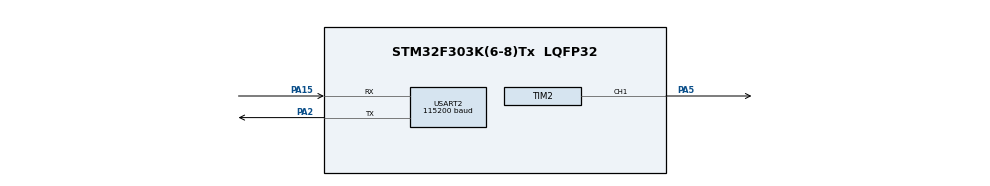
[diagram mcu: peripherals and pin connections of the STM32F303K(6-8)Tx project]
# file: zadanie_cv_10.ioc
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Dma.Request0=USART2_RX
Dma.Request1=USART2_TX
Dma.USART2_RX.0.Direction=DMA_PERIPH_TO_MEMORY
Dma.USART2_RX.0.Instance=DMA1_Channel6
Dma.USART2_RX.0.MemDataAlignment=DMA_MDATAALIGN_BYTE
Dma.USART2_RX.0.MemInc=DMA_MINC_ENABLE
Dma.USART2_RX.0.Mode=DMA_CIRCULAR
Dma.USART2_RX.0.PeriphDataAlignment=DMA_PDATAALIGN_BYTE
Dma.USART2_RX.0.PeriphInc=DMA_PINC_DISABLE
Dma.USART2_RX.0.Priority=DMA_PRIORITY_MEDIUM
Dma.USART2_TX.1.Direction=DMA_MEMORY_TO_PERIPH
Dma.USART2_TX.1.Instance=DMA1_Channel7
Dma.USART2_TX.1.MemDataAlignment=DMA_MDATAALIGN_BYTE
Dma.USART2_TX.1.MemInc=DMA_MINC_ENABLE
Dma.USART2_TX.1.Mode=DMA_NORMAL
Dma.USART2_TX.1.PeriphDataAlignment=DMA_PDATAALIGN_BYTE
Dma.USART2_TX.1.PeriphInc=DMA_PINC_DISABLE
Dma.USART2_TX.1.Priority=DMA_PRIORITY_MEDIUM
Mcu.Family=STM32F3
Mcu.Name=STM32F303K(6-8)Tx
Mcu.Package=LQFP32
NVIC.DMA1_Channel6_IRQn=true\:0\:0\:false\:false\:true\:false\:true
NVIC.DMA1_Channel7_IRQn=true\:0\:0\:false\:false\:true\:false\:true
NVIC.PriorityGroup=NVIC_PRIORITYGROUP_4
NVIC.TIM2_IRQn=true\:0\:0\:false\:false\:true\:true\:true
NVIC.USART2_IRQn=true\:0\:0\:false\:false\:true\:true\:true
PA15.Mode=Asynchronous
PA15.Signal=USART2_RX
PA2.Mode=Asynchronous
PA2.Signal=USART2_TX
PA5.Signal=S_TIM2_CH1_ETR
ProjectManager.HeapSize=0x200
ProjectManager.StackSize=0x400
ProjectManager.TargetToolchain=STM32CubeIDE
RCC.AHBFreq_Value=8000000
RCC.APB1Freq_Value=8000000
RCC.APB2Freq_Value=8000000
RCC.CortexFreq_Value=8000000
RCC.HSE_VALUE=8000000
RCC.HSI_VALUE=8000000
RCC.SYSCLKFreq_VALUE=8000000
SH.S_TIM2_CH1_ETR.0=TIM2_CH1,PWM Generation1 CH1
TIM2.Channel-PWM\ Generation1\ CH1=TIM_CHANNEL_1
TIM2.Period=9
TIM2.Prescaler=7999
USART2.BaudRate=115200
USART2.VirtualMode-Asynchronous=VM_ASYNC
VP_TIM2_VS_ClockSourceINT.Mode=Internal
board=NUCLEO-F303K8

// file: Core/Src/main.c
 /* USER CODE BEGIN Header */
/**
  ******************************************************************************
  * @file           : main.c
  * @brief          : Main program body
  ******************************************************************************
  * @attention
  *
  * <h2><center>&copy; Copyright (c) 2021 STMicroelectronics.
  * All rights reserved.</center></h2>
  *
  * This software component is licensed by ST under BSD 3-Clause license,
  * the "License"; You may not use this file except in compliance with the
  * License. You may obtain a copy of the License at:
  *                        opensource.org/licenses/BSD-3-Clause
  *
  ******************************************************************************
  */
/* USER CODE END Header */
#include "main.h"
#include "dma.h"
#include "tim.h"
#include "usart.h"
#include "gpio.h"
#include "stm32f3xx_it.h"
#include <string.h>

void SystemClock_Config(void);

/* USER CODE BEGIN 0 */
void proccesDmaData(const uint8_t* sign, uint8_t length);
/* USER CODE END 0 */
uint8_t is_dollar = 0;
uint8_t is_manual = 0;
int main(void)
{

  /* MCU Configuration--------------------------------------------------------*/

  /* Reset of all peripherals, Initializes the Flash interface and the Systick. */

  LL_APB2_GRP1_EnableClock(LL_APB2_GRP1_PERIPH_SYSCFG);
  LL_APB1_GRP1_EnableClock(LL_APB1_GRP1_PERIPH_PWR);

  NVIC_SetPriorityGrouping(NVIC_PRIORITYGROUP_4);

  /* System interrupt init*/

  /* Configure the system clock */
  SystemClock_Config();

  /* Initialize all configured peripherals */
  MX_GPIO_Init();
  MX_DMA_Init();
  MX_TIM2_Init();
  MX_USART2_UART_Init();
  /* USER CODE BEGIN 2 */
  USART2_RegisterCallback(proccesDmaData);

  uint8_t tx_data[500];

  /* USER CODE END 2 */

  /* Infinite loop */
  while (1)
  {
	  uint8_t buffer_mem_occupied = DMA_USART2_BUFFER_SIZE - LL_DMA_GetDataLength(DMA1, LL_DMA_CHANNEL_6);

	 	  float total_load = (float)buffer_mem_occupied/DMA_USART2_BUFFER_SIZE*100;

	 	  USART2_PutBuffer(tx_data, sprintf((char*)tx_data, "Buffer capacity: %d bytes, occupied memory: %d bytes, load [in %%]: %3.2f , pwm intensity: %d \n\r",\
	 	  								  DMA_USART2_BUFFER_SIZE,buffer_mem_occupied, total_load,intensity));
	 	  LL_mDelay(3000);

  }
}

void SystemClock_Config(void)
{
  LL_FLASH_SetLatency(LL_FLASH_LATENCY_0);
  while(LL_FLASH_GetLatency()!= LL_FLASH_LATENCY_0)
  {
  }
  LL_RCC_HSI_Enable();

   /* Wait till HSI is ready */
  while(LL_RCC_HSI_IsReady() != 1)
  {

  }
  LL_RCC_HSI_SetCalibTrimming(16);
  LL_RCC_SetAHBPrescaler(LL_RCC_SYSCLK_DIV_1);
  LL_RCC_SetAPB1Prescaler(LL_RCC_APB1_DIV_1);
  LL_RCC_SetAPB2Prescaler(LL_RCC_APB2_DIV_1);
  LL_RCC_SetSysClkSource(LL_RCC_SYS_CLKSOURCE_HSI);

   /* Wait till System clock is ready */
  while(LL_RCC_GetSysClkSource() != LL_RCC_SYS_CLKSOURCE_STATUS_HSI)
  {

  }
  LL_Init1msTick(8000000);
  LL_SetSystemCoreClock(8000000);
}

uint8_t pwm_intensity;

void proccesDmaData(const uint8_t* sign,uint8_t length)
{
	uint8_t cutted_str[8];
	uint8_t pwm_found = 0,str_pos = 0,pwm_pos = 0;
	uint8_t pwm_intensity_str[2];

	for(int i = 0; i< length; i++){

		if(*(sign+i) == '$'){
			is_dollar = 1;
		}

		if(is_dollar){
			cutted_str[str_pos] = *(sign+i);
			str_pos++;

			if(strstr(cutted_str,"$auto$")){
				is_manual = 0;
				memset(cutted_str,0,strlen(cutted_str));
				str_pos = 0;
				is_dollar = 0;
			}
			else if(strstr(cutted_str,"$manual$")){
				pwm_intensity = intensity;
				is_manual = 1;
				memset(cutted_str,0,strlen(cutted_str));
				str_pos = 0;
				is_dollar = 0;
			}

			if (pwm_found){
				if(pwm_pos == 2){
					if(cutted_str[str_pos-1] == '$'){
						sscanf(pwm_intensity_str, "%d", &pwm_intensity);
					}
					memset(pwm_intensity_str,0,strlen(pwm_intensity_str));
					pwm_found = 0;
					pwm_pos = 0;
					is_dollar = 0;
					str_pos = 0;
				}
				else if(cutted_str[str_pos-1]>= '0' && cutted_str[str_pos-1] <= '9'){
					pwm_intensity_str[pwm_pos] = cutted_str[str_pos-1];
					pwm_pos ++;

				}
			}
			if(is_manual && (strstr(cutted_str,"$PWM"))){
				pwm_found = 1;
			}
		}

		else {
			memset(cutted_str,0,strlen(cutted_str));
		}

	}

	return;
}

void setDutyCycle(uint8_t D){
	uint8_t pulse_length = 0;
	pulse_length = ((TIM2->ARR) * D) / 100;
	TIM2->CCR1 = pulse_length;
}

void Error_Handler(void)
{
  __disable_irq();
  while (1)
  {
  }
}

/************************ (C) COPYRIGHT STMicroelectronics *****END OF FILE****/
